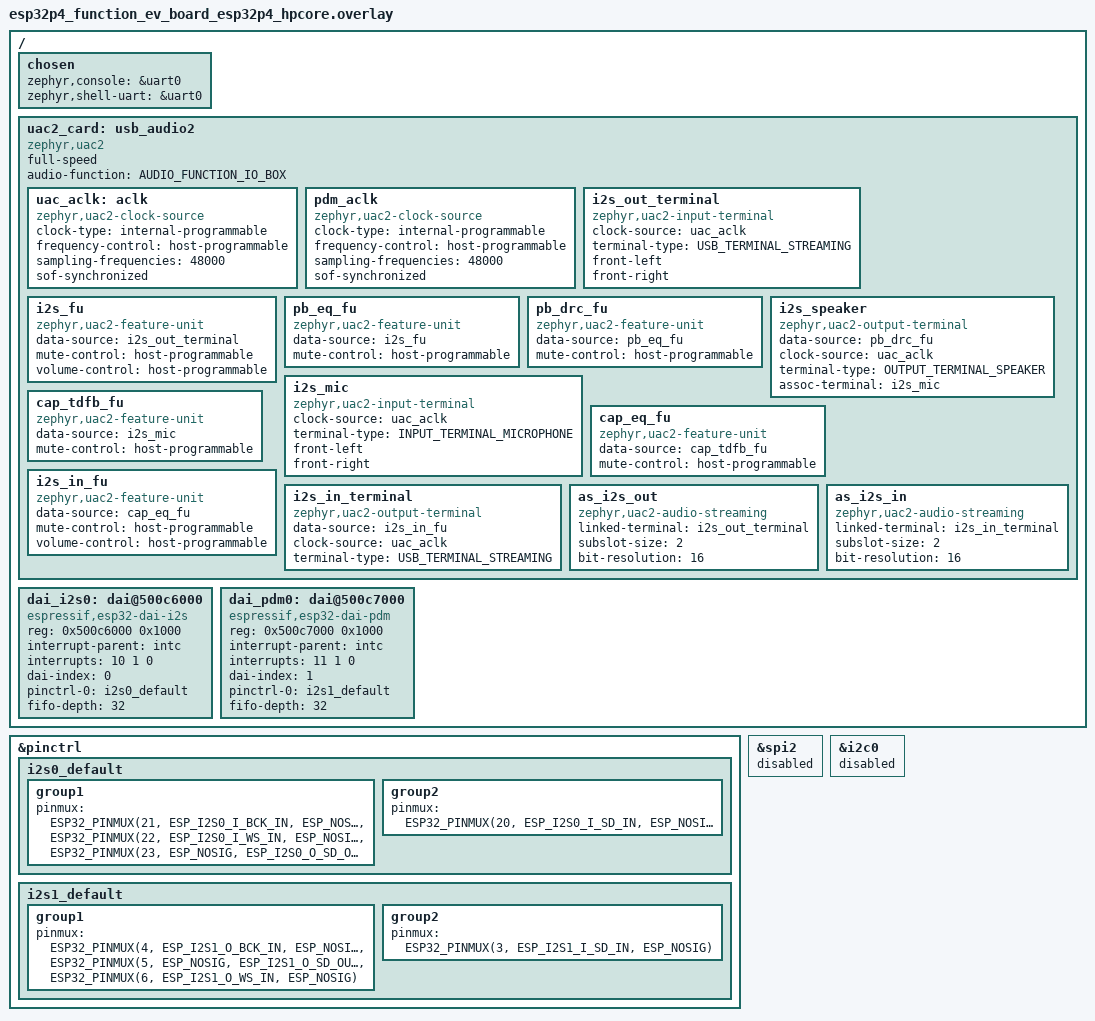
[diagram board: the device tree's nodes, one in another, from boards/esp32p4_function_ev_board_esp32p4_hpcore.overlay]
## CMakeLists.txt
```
# SPDX-License-Identifier: Apache-2.0

cmake_minimum_required(VERSION 3.21.0)

# Board specific overlays (these must be before find_package(Zephyr))
# -------------------------------------------------------------------

# Intel ACE3.x and newer (e.g. ptl, wcl, nvl): if "os_linux_overlay"
# used, also add "ll_userspace_overlay". The board target may be given
# in full in BOARD ("intel_adsp/ace30/ptl") or split into BOARD and
# BOARD_QUALIFIERS ("intel_adsp" + "ace30/ptl"), so match on both.
if(DEFINED EXTRA_CONF_FILE AND
   "${BOARD}/${BOARD_QUALIFIERS}" MATCHES "^intel_adsp/ace[3-9][0-9]/")
  string(FIND "${EXTRA_CONF_FILE}" "os_linux_overlay" _linux_overlay_idx)
  string(FIND "${EXTRA_CONF_FILE}" "ll_userspace_overlay" _ll_overlay_idx)
  if(_linux_overlay_idx GREATER_EQUAL 0 AND _ll_overlay_idx LESS 0)
    list(APPEND EXTRA_CONF_FILE
      "${CMAKE_CURRENT_SOURCE_DIR}/ll_userspace_overlay.conf")
  endif()
endif()

find_package(Zephyr HINTS $ENV{ZEPHYR_BASE})
project(sample_sof)

if(NOT ZEPHYR_SOF_MODULE)
  add_subdirectory(../zephyr sof_zephyr)
endif()

target_sources(app PRIVATE
    src/main.c
  )

target_sources_ifdef(CONFIG_USB_DEVICE_STACK_NEXT app PRIVATE
    src/usbd_init.c
  )

zephyr_library_include_directories(app PUBLIC
    ${CMAKE_CURRENT_SOURCE_DIR}/../src/include
  )

if(CONFIG_XTENSA)
  zephyr_library_include_directories(app PUBLIC
      ${CMAKE_CURRENT_SOURCE_DIR}/../src/arch/xtensa/include
    )
endif()

if(CONFIG_SOF_FULL_ZEPHYR_APPLICATION AND NOT CONFIG_XTENSA)
  target_include_directories(app PRIVATE
      ${CMAKE_CURRENT_SOURCE_DIR}/src
      ${CMAKE_CURRENT_SOURCE_DIR}/../zephyr/include
      ${CMAKE_CURRENT_SOURCE_DIR}/../src/platform/${PLATFORM}/include
      ${PROJECT_BINARY_DIR}/include/generated
    )

  target_link_libraries(app PRIVATE SOF -Wl,--start-group modules_sof sof_kernel -Wl,--end-group)
  if(TARGET uuid_reg_h)
    add_dependencies(app uuid_reg_h modules_sof sof_kernel)
  endif()
endif()

if(COMMAND sof_append_relative_path_definitions)
  sof_append_relative_path_definitions(app)
endif()
```

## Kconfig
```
config SCHED_CPU_MASK_PIN_ONLY
	default y if SMP

# Allow compiler to determine whether to generate FLIX instructions.
choice COMPILER_CODEGEN_VLIW
	default COMPILER_CODEGEN_VLIW_AUTO if "$(ZEPHYR_TOOLCHAIN_VARIANT)" = "xt-clang"
endchoice

source "Kconfig.zephyr"
osource "samples/subsys/usb/common/Kconfig.sample_usbd"

if !ZEPHYR_SOF_MODULE
rsource "../zephyr/Kconfig"
endif

if SOC_FAMILY_INTEL_ADSP
	rsource "boards/intel_adsp/Kconfig.defconfig"
endif
```

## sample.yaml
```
---
sample:
  description: Audio with SOF
  name: sof
common:
  tags: audio
  modules:
    - sof
tests:
  sample.audio.sof:
    tags: sof
    build_only: true
    platform_allow:
      - intel_adsp/cavs25
      - intel_adsp/ace15_mtpm
      - intel_adsp/ace20_lnl
      - intel_adsp/ace30/ptl
      - intel_adsp/ace30/ptl/sim
      - intel_adsp/ace30/wcl
      - intel_adsp/ace30/wcl/sim
      - intel_adsp/ace40/nvl
      - imx8qm_mek/mimx8qm6/adsp
      - imx8qxp_mek/mimx8qx6/adsp
      - imx8mp_evk/mimx8ml8/adsp
      - imx8ulp_evk/mimx8ud7/adsp

    integration_platforms:
      - intel_adsp/cavs25  # TGL
      - intel_adsp/ace15_mtpm  # MTL
      - intel_adsp/ace20_lnl
      - imx8qm_mek/mimx8qm6/adsp
      - imx8qxp_mek/mimx8qx6/adsp
      - imx8mp_evk/mimx8ml8/adsp
      - imx8ulp_evk/mimx8ud7/adsp
```

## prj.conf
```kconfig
CONFIG_BUILD_OUTPUT_BIN=n

# The additional stripped .elf files are deterministic.
# This adds very few files in the build directory and has
# absolutely no other effect whatsoever.
# See on-going discussion in
# https://github.com/zephyrproject-rtos/zephyr/pull/51954
# and usage in xtensa-build-zephyr.py
CONFIG_BUILD_OUTPUT_STRIPPED=y

CONFIG_HAVE_AGENT=n

# Since Zephyr commit f0daf904bb0202c PICOLIBC is the new default.
# We need more time to test and evaluate.
CONFIG_MINIMAL_LIBC=y

CONFIG_ZEPHYR_LOG=y
CONFIG_LOG=y
CONFIG_LOG_PRINTK=y
# Log processing is offloaded to a low-priority thread.
CONFIG_LOG_MODE_DEFERRED=y
# Wake the low-priority log thread every time new log
# messages are available
CONFIG_LOG_PROCESS_TRIGGER_THRESHOLD=1
# Frontend buffer must be large enough to cover all
# typical bursts of log messages.
CONFIG_LOG_BUFFER_SIZE=4096
# Use stack that is sufficient for SOF backends
CONFIG_LOG_PROCESS_THREAD_STACK_SIZE=4096
# Use Linux kernel style timestamp format
CONFIG_LOG_OUTPUT_FORMAT_LINUX_TIMESTAMP=y

# Requires heap_info() be implemented, but no Zephyr wrapper
CONFIG_DEBUG_MEMORY_USAGE_SCAN=n

# Ensure -O2 (or similar) is used for optimization
CONFIG_SPEED_OPTIMIZATIONS=y

# Zephyr top-level default of -fno-strict-overflow is
# not a good fit for audio DSP code
CONFIG_COMPILER_OPT="-fstrict-overflow"

CONFIG_SCHED_DEADLINE=y
CONFIG_SCHED_CPU_MASK=y

# Fix the sys ticks value  until following bugs are solved:
# - https://github.com/zephyrproject-rtos/zephyr/issues/46378
CONFIG_SYS_CLOCK_TICKS_PER_SEC=15000
CONFIG_DAI=y
CONFIG_HEAP_MEM_POOL_SIZE=2048
```

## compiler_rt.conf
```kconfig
CONFIG_COMPILER_RT_RTLIB=y
```

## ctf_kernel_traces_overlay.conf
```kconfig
# enable traces from Zephyr kernel

CONFIG_TRACING_BACKEND_ADSP_MEMORY_WINDOW=y
CONFIG_TRACING_ASYNC=n
CONFIG_TRACING_SYNC=y
CONFIG_TRACING=y
CONFIG_TRACING_CTF=y
CONFIG_THREAD_NAME=y
CONFIG_DEBUG_THREAD_INFO=y
```

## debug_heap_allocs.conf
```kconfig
# Use this overlay to increase log verbosity for
# all runtime heap allocs.
#
# Logs (LOG_INF) are emitted from all heap types (system heap 'sof_heap',
# virtual heap allocator, vregions, ...)
#

CONFIG_SYS_HEAP_RUNTIME_STATS=y
CONFIG_SYS_MEM_BLOCKS_RUNTIME_STATS=y
```

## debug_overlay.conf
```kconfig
CONFIG_DEBUG=y
CONFIG_ASSERT=y

CONFIG_ZTEST_NO_YIELD=n
CONFIG_ZTEST_SUMMARY=n
CONFIG_ZTEST_TEST_DELAY_MS=1
CONFIG_SOF_BOOT_TEST_ALLOWED=y
CONFIG_TEST_EXTRA_STACK_SIZE=7168

CONFIG_DAI_VERBOSE_GLITCH_WARNINGS=y

# Following options can be enabled additionally,
# but will incur a higher runtime cost, so are thus
# disabled by default.
#
# CONFIG_STACK_SENTINEL=y
# CONFIG_SYS_HEAP_VALIDATE=y
# CONFIG_SPIN_VALIDATE=y
# CONFIG_SPIN_LOCK_TIME_LIMIT=50000

CONFIG_COLD_STORE_EXECUTE_DEBUG=y

# GDB stub

CONFIG_GDBSTUB=y
CONFIG_GDBSTUB_ENTER_IMMEDIATELY=n

# Logging options
# Set default runtime log level to INFO (3) to maintain expected behavior in SOF CI.
# This ensures firmware starts with INFO level logging, same as previous configuration.
# Testing with runtime filtering enabled ensures the same feature set is validated.
# Note: This setting has no effect if CONFIG_LOG_RUNTIME_FILTERING is disabled.
CONFIG_LOG_RUNTIME_DEFAULT_LEVEL=3
```

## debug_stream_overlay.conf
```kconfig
# Enable debug-stream protocol
CONFIG_SOF_DEBUG_STREAM_SLOT=y
# Enable text message sending with ds_msg()
CONFIG_SOF_DEBUG_STREAM_TEXT_MSG=y
# Add thread_info-client for debug stream
CONFIG_SOF_DEBUG_STREAM_THREAD_INFO=y
# Zephyr option for storing human readable thread names
CONFIG_THREAD_NAME=y
# For Zephyr to compile with thread names on PTL we need to increase THREAD_BYTES
CONFIG_MAX_THREAD_BYTES=4
# Shrink number of CPU sections
# As the number of supported cores shrink, the available circular
# buffer size increases. This means increased bandwidth. This is
# particularly useful, when debugging a problem on core 0.
#CONFIG_SOF_DEBUG_STREAM_SLOT_FORCE_MAX_CPUS=1

# Direct the assert prints to debug stream
# This option obeys CONFIG_EXCEPTION_DUMP_HOOK_ONLY. If it is selected
# the assert print is sent only to debug stream. Without it the assert
# prints are printed with vprintk too,
CONFIG_SOF_DEBUG_STREAM_TEXT_MSG_ASSERT_PRINT=y

# Debug window slot configuration 1
# The CONFIG_SOF_TELEMETRY uses slot 2, but with performance and IO-performance
# it extends beyond slot 3.
CONFIG_MEMORY_WIN_2_SIZE=16384
CONFIG_SOF_TELEMETRY_PERFORMANCE_MEASUREMENTS=n
CONFIG_SOF_TELEMETRY_IO_PERFORMANCE_MEASUREMENTS=n

# If we turn telemetry off altogether, we can use slot 2. Slot 1 is used by mtrace
#CONFIG_SOF_DEBUG_STREAM_SLOT_NUMBER=2
#CONFIG_SOF_TELEMETRY=n
#CONFIG_SOF_TELEMETRY_PERFORMANCE_MEASUREMENTS=n
#CONFIG_SOF_TELEMETRY_IO_PERFORMANCE_MEASUREMENTS=n

# Enable Zephyr exception printing hook; debug stream is sensitive to this option too
CONFIG_EXCEPTION_DUMP_HOOK=y
# Do not try to send exception prints through logs; this causes problems on PTL with mtrace
CONFIG_EXCEPTION_DUMP_HOOK_ONLY=y
```

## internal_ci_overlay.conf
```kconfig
#
# Overlay definitions to build SOF firmware for internal CI
#
# The default SOF build (board config files) targets the Linux SOF
# driver. This overlay restores the configuration that was used
# for non-Linux builds before Linux became the default.
#
# When this overlay is used, app/CMakeLists.txt also:
#  - does not include the Intel ACE3.x+ LL userspace overlay
#    (ll_userspace_overlay.conf)
#  - includes the board specific internal CI overlay from
#    overlays/internal_ci/<board>.conf, if present
#

# Do not restrict firmware to features supported by stable
# Linux SOF driver versions. This also enables the additional
# virtual heap buffers (VIRTUAL_HEAP_EXTENDED) on platforms
# that support them.
CONFIG_SOF_OS_LINUX_COMPAT_PRIORITY=n
```

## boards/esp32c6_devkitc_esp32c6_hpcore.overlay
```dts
#include <zephyr/dt-bindings/interrupt-controller/esp-esp32c6-intmux.h>

/ {
	chosen {
		zephyr,console = &usb_serial;
		zephyr,shell-uart = &usb_serial;
	};

	dai_i2s0: dai@6000c000 {
		compatible = "espressif,esp32-dai-i2s";
		status = "okay";
		reg = <0x6000c000 0x1000>;
		interrupt-parent = <&intc>;
		interrupts = <I2S1_INTR_SOURCE IRQ_DEFAULT_PRIORITY 0>;
		dai-index = <0>;
		fifo-depth = <32>;
	};
};

&dma {
	status = "okay";
};

&usb_serial {
	status = "okay";
};

&i2c0 {
	status = "disabled";
};

&uart0 {
	status = "disabled";
};
```

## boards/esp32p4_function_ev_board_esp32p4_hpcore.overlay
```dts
#include <zephyr/dt-bindings/usb/audio.h>
#include <zephyr/dt-bindings/pinctrl/esp32p4-pinctrl.h>

/ {
	chosen {
		zephyr,console = &uart0;
		zephyr,shell-uart = &uart0;
	};

	uac2_card: usb_audio2 {
		compatible = "zephyr,uac2";
		status = "okay";
		full-speed;
		audio-function = <AUDIO_FUNCTION_IO_BOX>;

		uac_aclk: aclk {
			compatible = "zephyr,uac2-clock-source";
			clock-type = "internal-programmable";
			frequency-control = "host-programmable";
			sampling-frequencies = <48000>;
			sof-synchronized;
		};

		pdm_aclk: pdm_aclk {
			compatible = "zephyr,uac2-clock-source";
			clock-type = "internal-programmable";
			frequency-control = "host-programmable";
			sampling-frequencies = <48000>;
			sof-synchronized;
		};

		/* ===== Playback from Host (ISO OUT) ===== */
		i2s_out_terminal: i2s_out_terminal {
			compatible = "zephyr,uac2-input-terminal";
			clock-source = <&uac_aclk>;
			terminal-type = <USB_TERMINAL_STREAMING>;
			front-left;
			front-right;
		};

		i2s_fu: i2s_fu {
			compatible = "zephyr,uac2-feature-unit";
			data-source = <&i2s_out_terminal>;
			mute-control = "host-programmable";
			volume-control = "host-programmable";
		};

		pb_eq_fu: pb_eq_fu {
			compatible = "zephyr,uac2-feature-unit";
			data-source = <&i2s_fu>;
			mute-control = "host-programmable";
		};

		pb_drc_fu: pb_drc_fu {
			compatible = "zephyr,uac2-feature-unit";
			data-source = <&pb_eq_fu>;
			mute-control = "host-programmable";
		};

		i2s_speaker: i2s_speaker {
			compatible = "zephyr,uac2-output-terminal";
			data-source = <&pb_drc_fu>;
			clock-source = <&uac_aclk>;
			terminal-type = <OUTPUT_TERMINAL_SPEAKER>;
			assoc-terminal = <&i2s_mic>;
		};

		/* ===== Capture to Host (ISO IN) ===== */
		i2s_mic: i2s_mic {
			compatible = "zephyr,uac2-input-terminal";
			clock-source = <&uac_aclk>;
			terminal-type = <INPUT_TERMINAL_MICROPHONE>;
			front-left;
			front-right;
		};

		cap_tdfb_fu: cap_tdfb_fu {
			compatible = "zephyr,uac2-feature-unit";
			data-source = <&i2s_mic>;
			mute-control = "host-programmable";
		};

		cap_eq_fu: cap_eq_fu {
			compatible = "zephyr,uac2-feature-unit";
			data-source = <&cap_tdfb_fu>;
			mute-control = "host-programmable";
		};

		i2s_in_fu: i2s_in_fu {
			compatible = "zephyr,uac2-feature-unit";
			data-source = <&cap_eq_fu>;
			mute-control = "host-programmable";
			volume-control = "host-programmable";
		};

		i2s_in_terminal: i2s_in_terminal {
			compatible = "zephyr,uac2-output-terminal";
			data-source = <&i2s_in_fu>;
			clock-source = <&uac_aclk>;
			terminal-type = <USB_TERMINAL_STREAMING>;
		};

		/* Audio Streaming Interfaces */
		as_i2s_out: as_i2s_out {
			compatible = "zephyr,uac2-audio-streaming";
			linked-terminal = <&i2s_out_terminal>;
			subslot-size = <2>;
			bit-resolution = <16>;
		};

		as_i2s_in: as_i2s_in {
			compatible = "zephyr,uac2-audio-streaming";
			linked-terminal = <&i2s_in_terminal>;
			subslot-size = <2>;
			bit-resolution = <16>;
		};
	};

	/* ESP32 DAI Nodes */
	dai_i2s0: dai@500c6000 {
		compatible = "espressif,esp32-dai-i2s";
		status = "okay";
		reg = <0x500c6000 0x1000>;
		interrupt-parent = <&intc>;
		interrupts = <10 1 0>;
		dai-index = <0>;
		pinctrl-0 = <&i2s0_default>;
		pinctrl-names = "default";
		fifo-depth = <32>;
	};

	dai_pdm0: dai@500c7000 {
		compatible = "espressif,esp32-dai-pdm";
		status = "okay";
		reg = <0x500c7000 0x1000>;
		interrupt-parent = <&intc>;
		interrupts = <11 1 0>;
		dai-index = <1>;
		pinctrl-0 = <&i2s1_default>;
		pinctrl-names = "default";
		fifo-depth = <32>;
	};
};

&pinctrl {
	i2s0_default: i2s0_default {
		group1 {
			pinmux = <ESP32_PINMUX(21, ESP_I2S0_I_BCK_IN, ESP_NOSIG)>,
				 <ESP32_PINMUX(22, ESP_I2S0_I_WS_IN, ESP_NOSIG)>,
				 <ESP32_PINMUX(23, ESP_NOSIG, ESP_I2S0_O_SD_OUT)>;
		};
		group2 {
			pinmux = <ESP32_PINMUX(20, ESP_I2S0_I_SD_IN, ESP_NOSIG)>;
		};
	};

	i2s1_default: i2s1_default {
		group1 {
			pinmux = <ESP32_PINMUX(4, ESP_I2S1_O_BCK_IN, ESP_NOSIG)>,
				 <ESP32_PINMUX(5, ESP_NOSIG, ESP_I2S1_O_SD_OUT)>,
				 <ESP32_PINMUX(6, ESP_I2S1_O_WS_IN, ESP_NOSIG)>;
		};
		group2 {
			pinmux = <ESP32_PINMUX(3, ESP_I2S1_I_SD_IN, ESP_NOSIG)>;
		};
	};
};

&spi2 {
	status = "disabled";
};

&i2c0 {
	status = "disabled";
};
```

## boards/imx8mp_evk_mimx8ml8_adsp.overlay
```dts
/*
 * Copyright 2024 NXP
 *
 * SPDX-License-Identifier: Apache-2.0
 */

/ {
	host_dma: dma {
		compatible = "nxp,sof-host-dma";
		dma-channels = <32>;
		#dma-cells = <0>;
	};
};

&sdma3 {
	status = "okay";
};

&sai3 {
	rx-fifo-watermark = <65>;
	tx-fifo-watermark = <65>;
	fifo-depth = <128>;
	rx-sync-mode = <1>;
	status = "okay";
};

&micfil {
	status = "okay";
};
```

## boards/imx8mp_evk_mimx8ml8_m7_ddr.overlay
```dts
/*
 * Copyright 2026 NXP
 *
 * SPDX-License-Identifier: Apache-2.0
 */

/ {
	host_dma: dma {
		compatible = "nxp,sof-host-dma";
		dma-channels = <32>;
		#dma-cells = <0>;
	};
};

&sdma3 {
	status = "okay";
};

&sai3 {
	pinctrl-0 = <&sai3_default>;
	pinctrl-names = "default";
	rx-fifo-watermark = <64>;
	tx-fifo-watermark = <64>;
	fifo-depth = <96>;
	rx-sync-mode = <1>;
	status = "okay";
};
```

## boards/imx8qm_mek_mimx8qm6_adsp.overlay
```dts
/*
 * Copyright 2023 NXP
 *
 * SPDX-License-Identifier: Apache-2.0
 */

/ {
	host_dma: dma {
		compatible = "nxp,sof-host-dma";
		dma-channels = <32>;
		#dma-cells = <0>;
	};
};

&lpuart2 {
	/* note for developers: this is disabled
	 * because the firmware running on one of the M4
	 * cores uses the same LPUART instance. As such,
	 * to debug you need to make sure that:
	 *	1) Your SOF DTS doesn't include the RPMSG
	 *	DTS but instead the base DTS (which is
	 *	"imx8qm-mek.dts")
	 *	2) Your u-boot doesn't include the M4 firmware
	 *	images.
	 */
	status = "disabled";
};

&sai1 {
	rx-fifo-watermark = <48>;
	tx-fifo-watermark = <2>;
	fifo-depth = <48>;
	rx-sync-mode = <1>;
	status = "okay";
};

&esai0 {
	fifo-depth = <96>;
	/* note: not the same semantic as SAI TX watermark. For ESAI
	 * the DMA requests are generated when number of empty slots
	 * in the transmit FIFO reaches the chosen watermark value.
	 * In this case, DMA requests will be generated when transmit
	 * FIFO has 128 empty slots (equivalent to the FIFO having
	 * 2 words since the FIFO depth is 128 words).
	 */
	tx-fifo-watermark = <126>;
	rx-fifo-watermark = <96>;
	/* needed for internal CS42888 workaround. Remove when possible */
	esai-clock-configuration = <ESAI_CLOCK_SCKR ESAI_CLOCK_INPUT>,
				<ESAI_CLOCK_FSR ESAI_CLOCK_INPUT>;
	status = "okay";
};

&edma0 {
	status = "okay";
};
```

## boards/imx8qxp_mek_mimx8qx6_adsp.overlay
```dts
/*
 * Copyright 2023 NXP
 *
 * SPDX-License-Identifier: Apache-2.0
 */

/ {
	host_dma: dma {
		compatible = "nxp,sof-host-dma";
		dma-channels = <32>;
		#dma-cells = <0>;
	};
};

&sai1 {
	rx-fifo-watermark = <48>;
	tx-fifo-watermark = <2>;
	fifo-depth = <48>;
	rx-sync-mode = <1>;
	status = "okay";
};

&esai0 {
	fifo-depth = <96>;
	/* note: not the same semantic as SAI TX watermark. For ESAI
	* the DMA requests are generated when number of empty slots
	* in transmit FIFO reaches the chosen watermark value.
	* In this case, DMA requests will be generated when transmit
	* FIFO has 126 empty slots (equivalent to the FIFO having
	* 2 words since the FIFO depth is 128 words).
	*/
	tx-fifo-watermark = <126>;
	rx-fifo-watermark = <96>;
	/* needed for internal CS42888 workaround. Remove when possible */
	esai-clock-configuration = <ESAI_CLOCK_SCKR ESAI_CLOCK_INPUT>,
				<ESAI_CLOCK_FSR ESAI_CLOCK_INPUT>;
	status = "okay";
};

&edma0 {
	status = "okay";
};
```

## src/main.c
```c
/*
 * Copyright (c) 2020 Intel Corporation.
 *
 * SPDX-License-Identifier: Apache-2.0
 */

#include <zephyr/kernel.h>
#include <sof/boot_test.h>
#include <zephyr/logging/log.h>

#if defined(CONFIG_PLATFORM_TEENSY41)
#include <zephyr/device.h>
#include <zephyr/usb/usbd.h>
#include <zephyr/usb/class/usbd_uac2.h>
#include <sample_usbd.h>
#include <sof/platform.h>
#include <sof/audio/pipeline/static_pipeline.h>
#endif

LOG_MODULE_REGISTER(main, LOG_LEVEL_DBG);

/* define qemu boot tests if any qemu target is defined, add targets to end */
#if defined(CONFIG_BOARD_QEMU_XTENSA_DC233C) ||\
    defined(CONFIG_BOARD_QEMU_XTENSA_DC233C_MMU)
#define QEMU_BOOT_TESTS
#endif

/**
 * Should be included from sof/schedule/task.h
 * but triggers include chain issue
 * FIXME
 */
int sof_main(int argc, char *argv[]);

/**
 * TODO: Here comes SOF initialization
 */

static int sof_app_main(void)
{
	int ret;

	LOG_INF("SOF on %s", CONFIG_BOARD);

	/* sof_main is actually SOF initialization */
	ret = sof_main(0, NULL);
	if (ret) {
		LOG_ERR("SOF initialization failed");
	}

	LOG_INF("SOF initialized");

#if defined(CONFIG_PLATFORM_TEENSY41)
	ret = sof_static_topology_init(&g_teensy41_static_topology);
	if (ret < 0) {
		LOG_ERR("Static topology initialization failed: %d", ret);
		return ret;
	}

	const struct device *uac2_dev = DEVICE_DT_GET_ONE(zephyr_uac2);

	if (device_is_ready(uac2_dev)) {
		usbd_uac2_set_ops(uac2_dev, sof_static_uac2_get_ops(), NULL);
	} else {
		LOG_ERR("UAC2 device not ready");
	}

	struct usbd_context *sample_usbd = sample_usbd_init_device(NULL);

	if (sample_usbd) {
		usbd_enable(sample_usbd);
		LOG_INF("SOF USB UAC2 device and static pipelines started");
	} else {
		LOG_ERR("Failed to initialize USB device context");
	}
#endif

#ifdef CONFIG_ARCH_POSIX_LIBFUZZER
	/* Workaround for an apparent timing bug in libfuzzer+asan.
	 * If the initial/main thread is allowed to return, ASAN will
	 * fairly reliably report a "stack overflow" where the ESP and
	 * EPC (instruction pointer!) registers are both set to the
	 * same value, which is non-sensical.  See some discussion in
	 * https://github.com/zephyrproject-rtos/zephyr/pull/52769
	 *
	 * But suspending the main thread instead of aborting is cheap
	 * and easy.
	 */
	k_thread_suspend(k_current_get());
#endif
	return 0;
}

#if defined(QEMU_BOOT_TESTS)
/* cleanly exit qemu so CI can continue and check test results */
static inline void qemu_xtensa_exit(int status)
{
	register int syscall_id __asm__ ("a2") = 1;      /* SYS_exit is 1 */
	register int exit_status __asm__ ("a3") = status;

	__asm__ __volatile__ (
		"simcall\n"
		:
		: "r" (syscall_id), "r" (exit_status)
		: "memory"
	);
}
#endif

#ifdef CONFIG_REBOOT
void sys_arch_reboot(int type)
{
#if defined(QEMU_BOOT_TESTS)
	qemu_xtensa_exit(type);
#endif
	while (1) {
		k_cpu_idle();
	}
}
#endif

#if CONFIG_ZTEST
void test_main(void)
{
	sof_app_main();
#if CONFIG_SOF_BOOT_TEST && (defined(QEMU_BOOT_TESTS) || CONFIG_SOF_BOOT_TEST_STANDALONE)
	sof_run_boot_tests();
#if defined(QEMU_BOOT_TESTS)
	/* qemu_xtensa_exit() only exists for QEMU targets; a standalone
	 * boot test (e.g. native_sim) just returns from test_main()
	 */
	qemu_xtensa_exit(0);
#endif
#endif
}
#else
int main(void)
{
	return sof_app_main();
}
#endif
```

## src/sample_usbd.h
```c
/*
 * Copyright (c) 2023 Nordic Semiconductor ASA.
 *
 * SPDX-License-Identifier: Apache-2.0
 */

#ifndef ZEPHYR_SAMPLES_SUBSYS_USB_COMMON_SAMPLE_USBD_H
#define ZEPHYR_SAMPLES_SUBSYS_USB_COMMON_SAMPLE_USBD_H

#include <stdint.h>
#include <zephyr/usb/usbd.h>

struct usbd_context *sample_usbd_init_device(usbd_msg_cb_t msg_cb);
struct usbd_context *sample_usbd_setup_device(usbd_msg_cb_t msg_cb);

#endif /* ZEPHYR_SAMPLES_SUBSYS_USB_COMMON_SAMPLE_USBD_H */
```

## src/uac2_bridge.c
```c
// SPDX-License-Identifier: BSD-3-Clause
/*
 * Copyright (c) 2026 Sound Open Firmware (SOF) Project
 */

#include "uac2_bridge.h"
#include <sof/audio/pipeline/static_pipeline.h>
#include <sof/audio/usb_audio.h>
#if CONFIG_COMP_BT_AUDIO
#include <sof/audio/bt_audio.h>
#include <sof/audio/bt_service.h>
#endif
#include <zephyr/logging/log.h>
#include <zephyr/usb/usbd.h>
#include <zephyr/usb/class/usbd_uac2.h>
#include <zephyr/device.h>

LOG_MODULE_REGISTER(uac2_bridge, CONFIG_SOF_LOG_LEVEL);

#if defined(CONFIG_USBD_AUDIO2_CLASS)
#define PLAYBACK_FU_ID       UAC2_ENTITY_ID(DT_NODELABEL(i2s_fu))
#define PLAYBACK_EQ_FU_ID    UAC2_ENTITY_ID(DT_NODELABEL(pb_eq_fu))
#define PLAYBACK_DRC_FU_ID   UAC2_ENTITY_ID(DT_NODELABEL(pb_drc_fu))
#define CAPTURE_EQ_FU_ID     UAC2_ENTITY_ID(DT_NODELABEL(cap_eq_fu))
#define CAPTURE_FU_ID        UAC2_ENTITY_ID(DT_NODELABEL(i2s_in_fu))
#define PLAYBACK_TERM_ID     UAC2_ENTITY_ID(DT_NODELABEL(i2s_out_terminal))
#define CAPTURE_TERM_ID      UAC2_ENTITY_ID(DT_NODELABEL(i2s_in_terminal))
#else
#define PLAYBACK_FU_ID       1
#define PLAYBACK_EQ_FU_ID    2
#define PLAYBACK_DRC_FU_ID   3
#define CAPTURE_EQ_FU_ID     4
#define CAPTURE_FU_ID        5
#define PLAYBACK_TERM_ID     6
#define CAPTURE_TERM_ID      7
#endif

#if defined(CONFIG_NOCACHE_MEMORY)
K_MEM_SLAB_DEFINE_IN_SECT_STATIC(uac2_rx_slab, __nocache, 256, 32, 64);
K_MEM_SLAB_DEFINE_IN_SECT_STATIC(uac2_tx_slab, __nocache, 256, 64, 64);
#else
K_MEM_SLAB_DEFINE_STATIC(uac2_rx_slab, 256, 32, 64);
K_MEM_SLAB_DEFINE_STATIC(uac2_tx_slab, 256, 64, 64);
#endif

static struct {
	bool playback_active;
	bool capture_active;
	bool microframes;
	uint32_t sample_rate;
	int16_t playback_volume;
	bool playback_mute;
	int16_t capture_volume;
	bool capture_mute;
} g_uac2_state = {
	.sample_rate = 48000,
};

static uint32_t s_sof_diag_cnt;

static void sof_uac2_send_capture_pending(const struct device *dev)
{
	if (!g_uac2_state.capture_active || !dev) {
		return;
	}

	uint32_t rate = g_uac2_state.sample_rate ? g_uac2_state.sample_rate : 48000;
	uint32_t frame_bytes;

	if (g_uac2_state.microframes) {
		frame_bytes = (rate / 8000) * 4;
	} else {
		frame_bytes = (rate / 1000) * 4;
	}
	if (frame_bytes == 0 || frame_bytes > 512) {
		frame_bytes = g_uac2_state.microframes ? 24 : 192;
	}

#if CONFIG_COMP_BT_AUDIO
	if (bt_service_get_route() != SOF_AUDIO_ROUTE_USB_BT &&
	    !usb_audio_has_capture_data(frame_bytes)) {
		return;
	}
#else
	if (!usb_audio_has_capture_data(frame_bytes)) {
		return;
	}
#endif

	for (int iter = 0; iter < 2; iter++) {
		void *buf = NULL;
		if (k_mem_slab_alloc(&uac2_tx_slab, &buf, K_NO_WAIT) != 0) {
			static uint32_t s_slab_alloc_fails;
			s_slab_alloc_fails++;
			if (s_slab_alloc_fails <= 5 || s_slab_alloc_fails % 100 == 0) {
				LOG_WRN("Failed to allocate UAC2 TX slab block (%u)",
					s_slab_alloc_fails);
			}
			break;
		}

		bool have_data = false;
#if CONFIG_COMP_BT_AUDIO
		if (bt_service_get_route() == SOF_AUDIO_ROUTE_USB_BT) {
			have_data = bt_audio_peek_capture_data(buf, frame_bytes);
		} else
#endif
		{
			have_data = usb_audio_peek_capture_data(buf, frame_bytes);
		}

		if (!have_data) {
			k_mem_slab_free(&uac2_tx_slab, buf);
			break;
		}

		if (g_uac2_state.capture_mute) {
			memset(buf, 0, frame_bytes);
		}

		int ret = usbd_uac2_send(dev, CAPTURE_TERM_ID, buf, frame_bytes);
		if (ret == 0) {
			if (!g_uac2_state.capture_mute) {
#if CONFIG_COMP_BT_AUDIO
				if (bt_service_get_route() == SOF_AUDIO_ROUTE_USB_BT) {
					bt_audio_consume_capture_data(frame_bytes);
				} else
#endif
				{
					usb_audio_consume_capture_data(frame_bytes);
				}
			}
		} else {
			k_mem_slab_free(&uac2_tx_slab, buf);
			break;
		}
	}
}

static void sof_uac2_sof_cb(const struct device *dev, void *user_data)
{
	ARG_UNUSED(user_data);

	if (g_uac2_state.playback_active || g_uac2_state.capture_active) {
		s_sof_diag_cnt++;
		if (s_sof_diag_cnt % 1000 == 0) {
			LOG_DBG("[DIAG SOF %u] Active streaming", s_sof_diag_cnt);
		}
	} else {
		s_sof_diag_cnt = 0;
	}

	if (g_uac2_state.capture_active && dev) {
		sof_uac2_send_capture_pending(dev);
	}
}

static void sof_uac2_terminal_update_cb(const struct device *dev, uint8_t terminal,
					bool enabled, bool microframes, void *user_data)
{
	ARG_UNUSED(dev);
	ARG_UNUSED(user_data);

	LOG_INF("[UAC2 Terminal] update: terminal %u, enabled %d, microframes %d",
		terminal, enabled, microframes);

	g_uac2_state.microframes = microframes;

	if (terminal == PLAYBACK_TERM_ID) {
		g_uac2_state.playback_active = enabled;
		sof_static_pipeline_trigger_by_uac2_term(terminal, enabled);
	} else if (terminal == CAPTURE_TERM_ID) {
		g_uac2_state.capture_active = enabled;
		sof_static_pipeline_trigger_by_uac2_term(terminal, enabled);
	}
}

static void *sof_uac2_get_recv_buf(const struct device *dev, uint8_t terminal,
				   uint16_t size, void *user_data)
{
	ARG_UNUSED(dev);
	ARG_UNUSED(terminal);
	ARG_UNUSED(size);
	ARG_UNUSED(user_data);

	void *buf = NULL;
	if (k_mem_slab_alloc(&uac2_rx_slab, &buf, K_NO_WAIT) != 0) {
		return NULL;
	}
	return buf;
}

static void sof_uac2_data_recv_cb(const struct device *dev, uint8_t terminal,
				  void *buf, uint16_t size, void *user_data)
{
	ARG_UNUSED(dev);
	ARG_UNUSED(terminal);
	ARG_UNUSED(user_data);

	if (buf && size > 0) {
		if (g_uac2_state.playback_mute) {
			memset(buf, 0, size);
		}
#if CONFIG_COMP_BT_AUDIO
		if (bt_service_get_route() == SOF_AUDIO_ROUTE_BT_DAI) {
			bt_audio_write_playback(buf, size);
		} else
#endif
		{
			usb_audio_feed_playback_data(buf, size);
		}
	}
}

static void sof_uac2_buf_release(const struct device *dev, uint8_t terminal,
				 void *buf, void *user_data)
{
	ARG_UNUSED(user_data);

	if (buf) {
		k_mem_slab_free(&uac2_tx_slab, buf);
	}

	if (terminal == CAPTURE_TERM_ID && dev) {
		sof_uac2_send_capture_pending(dev);
	}
}

static uint32_t sof_uac2_get_sample_rate(const struct device *dev, uint8_t clock_id,
					 void *user_data)
{
	ARG_UNUSED(dev);
	ARG_UNUSED(clock_id);
	ARG_UNUSED(user_data);

	return g_uac2_state.sample_rate ? g_uac2_state.sample_rate : 48000;
}

static int sof_uac2_set_sample_rate(const struct device *dev, uint8_t clock_id,
				    uint32_t rate, void *user_data)
{
	ARG_UNUSED(dev);
	ARG_UNUSED(clock_id);
	ARG_UNUSED(user_data);

	LOG_INF("Host set sample rate: %u Hz", rate);
	g_uac2_state.sample_rate = rate;
	sof_static_set_sample_rate(rate);
	usb_audio_set_playback_rate(rate);
	usb_audio_set_capture_rate(rate);
	return 0;
}

enum usbd_speed sample_usbd_get_speed(void);

static uint32_t sof_uac2_feedback_cb(const struct device *dev, uint8_t terminal,
				     void *user_data)
{
	ARG_UNUSED(dev);
	ARG_UNUSED(terminal);
	ARG_UNUSED(user_data);

	uint32_t rate = g_uac2_state.sample_rate ? g_uac2_state.sample_rate : 48000;

	if (sample_usbd_get_speed() == USBD_SPEED_HS) {
		return (uint32_t)(((uint64_t)rate << 16) / 8000);
	} else {
		return (uint32_t)(((uint64_t)rate << 14) / 1000);
	}
}

static int sof_uac2_set_feature_mute(const struct device *dev, uint8_t entity_id,
				     uint8_t channel, bool mute, void *user_data)
{
	ARG_UNUSED(dev);
	ARG_UNUSED(user_data);

	LOG_DBG("Host set mute/switch: entity=%u, ch=%u, mute=%d", entity_id, channel, mute);
	if (entity_id == PLAYBACK_FU_ID) {
		g_uac2_state.playback_mute = mute;
	} else if (entity_id == CAPTURE_FU_ID) {
		g_uac2_state.capture_mute = mute;
	}

	return sof_static_kcontrol_set_by_uac2(entity_id, channel, mute ? 1 : 0, false);
}

static int sof_uac2_get_feature_mute(const struct device *dev, uint8_t entity_id,
				     uint8_t channel, bool *mute, void *user_data)
{
	ARG_UNUSED(dev);
	ARG_UNUSED(user_data);

	if (!mute) {
		return -EINVAL;
	}

	if (entity_id == PLAYBACK_FU_ID) {
		*mute = g_uac2_state.playback_mute;
		return 0;
	} else if (entity_id == CAPTURE_FU_ID) {
		*mute = g_uac2_state.capture_mute;
		return 0;
	}

	int32_t val = 0;
	int ret = sof_static_kcontrol_get_by_uac2(entity_id, channel, &val, false);
	*mute = (ret == 0) ? (val != 0) : false;
	return 0;
}

static int sof_uac2_set_feature_volume(const struct device *dev, uint8_t entity_id,
				       uint8_t channel, int16_t volume, void *user_data)
{
	ARG_UNUSED(dev);
	ARG_UNUSED(user_data);

	LOG_DBG("Host set volume: entity=%u, ch=%u, vol=%d", entity_id, channel, volume);
	if (entity_id == PLAYBACK_FU_ID) {
		g_uac2_state.playback_volume = volume;
	} else if (entity_id == CAPTURE_FU_ID) {
		g_uac2_state.capture_volume = volume;
	}

	return sof_static_kcontrol_set_by_uac2(entity_id, channel, volume, true);
}

static int sof_uac2_get_feature_volume(const struct device *dev, uint8_t entity_id,
				       uint8_t channel, int16_t *volume, void *user_data)
{
	ARG_UNUSED(dev);
	ARG_UNUSED(user_data);

	if (!volume) {
		return -EINVAL;
	}

	if (entity_id == PLAYBACK_FU_ID) {
		*volume = g_uac2_state.playback_volume;
		return 0;
	} else if (entity_id == CAPTURE_FU_ID) {
		*volume = g_uac2_state.capture_volume;
		return 0;
	}

	int32_t val = 0;
	int ret = sof_static_kcontrol_get_by_uac2(entity_id, channel, &val, true);
	*volume = (ret == 0) ? (int16_t)val : 0;
	return 0;
}

static const struct uac2_ops g_uac2_ops = {
	.sof_cb = sof_uac2_sof_cb,
	.terminal_update_cb = sof_uac2_terminal_update_cb,
	.get_recv_buf = sof_uac2_get_recv_buf,
	.data_recv_cb = sof_uac2_data_recv_cb,
	.buf_release_cb = sof_uac2_buf_release,
	.feedback_cb = sof_uac2_feedback_cb,
	.get_sample_rate = sof_uac2_get_sample_rate,
	.set_sample_rate = sof_uac2_set_sample_rate,
	.set_feature_mute = sof_uac2_set_feature_mute,
	.get_feature_mute = sof_uac2_get_feature_mute,
	.set_feature_volume = sof_uac2_set_feature_volume,
	.get_feature_volume = sof_uac2_get_feature_volume,
};

const struct uac2_ops *sof_get_uac2_ops(void)
{
	return &g_uac2_ops;
}

#if defined(CONFIG_PLATFORM_NRF54L15)
extern const struct sof_static_topology g_nrf54l15_static_topology;
#elif defined(CONFIG_PLATFORM_NRF54LM20)
extern const struct sof_static_topology g_nrf54lm20_static_topology;
#endif

int sof_static_pipelines_init(struct sof *sof)
{
	ARG_UNUSED(sof);
#if defined(CONFIG_PLATFORM_NRF54L15)
	int ret = sof_static_topology_init(&g_nrf54l15_static_topology);
	if (ret < 0)
		return ret;

	sof_static_pipeline_trigger(1, true);
	return 0;
#elif defined(CONFIG_PLATFORM_NRF54LM20)
	int ret = sof_static_topology_init(&g_nrf54lm20_static_topology);
	if (ret < 0)
		return ret;

	sof_static_pipeline_trigger(1, true);
	sof_static_pipeline_trigger(2, true);
	return 0;
#else
	return -ENODEV;
#endif
}
```

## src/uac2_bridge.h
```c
/* SPDX-License-Identifier: BSD-3-Clause
 *
 * Copyright (c) 2026 Sound Open Firmware (SOF) Project
 */

#ifndef __APP_UAC2_BRIDGE_H__
#define __APP_UAC2_BRIDGE_H__

struct sof;
struct uac2_ops;

/**
 * \brief Initialize static audio pipelines for the active Nordic platform.
 * \param[in] sof SOF context pointer.
 * \return 0 on success, negative errno on failure.
 */
int sof_static_pipelines_init(struct sof *sof);

/**
 * \brief Return the Zephyr USB Audio Class 2.0 callback table.
 * \return Pointer to static uac2_ops structure.
 */
const struct uac2_ops *sof_get_uac2_ops(void);

#endif /* __APP_UAC2_BRIDGE_H__ */
```

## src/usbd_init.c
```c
/*
 * Copyright (c) 2023 Nordic Semiconductor ASA
 * Copyright (c) 2026 Sound Open Firmware (SOF) Project
 *
 * SPDX-License-Identifier: Apache-2.0
 */

#include <stdint.h>

#include <zephyr/device.h>
#include <zephyr/usb/usbd.h>
#include <zephyr/usb/bos.h>
#include <zephyr/logging/log.h>
#include <sample_usbd.h>

LOG_MODULE_REGISTER(usbd_sample_config, LOG_LEVEL_INF);

static const char *const blocklist[] = {
	"dfu_dfu",
	NULL,
};

USBD_DEVICE_DEFINE(sample_usbd,
		   DEVICE_DT_GET(DT_NODELABEL(zephyr_udc0)),
		   CONFIG_SAMPLE_USBD_VID, CONFIG_SAMPLE_USBD_PID);

USBD_DESC_LANG_DEFINE(sample_lang);
USBD_DESC_MANUFACTURER_DEFINE(sample_mfr, CONFIG_SAMPLE_USBD_MANUFACTURER);

#if defined(CONFIG_PLATFORM_TEENSY41) && defined(CONFIG_TEENSY41_BOARD_B)
USBD_DESC_PRODUCT_DEFINE(sample_product, "SOF Teensy 4.1 Audio B");
#elif defined(CONFIG_PLATFORM_TEENSY41) && defined(CONFIG_TEENSY41_BOARD_A)
USBD_DESC_PRODUCT_DEFINE(sample_product, "SOF Teensy 4.1 Audio A");
#else
USBD_DESC_PRODUCT_DEFINE(sample_product, CONFIG_SAMPLE_USBD_PRODUCT);
#endif

IF_ENABLED(CONFIG_HWINFO, (USBD_DESC_SERIAL_NUMBER_DEFINE(sample_sn)));

USBD_DESC_CONFIG_DEFINE(fs_cfg_desc, "FS Configuration");
USBD_DESC_CONFIG_DEFINE(hs_cfg_desc, "HS Configuration");

static const uint8_t attributes = (IS_ENABLED(CONFIG_SAMPLE_USBD_SELF_POWERED) ?
				   USB_SCD_SELF_POWERED : 0) |
				  (IS_ENABLED(CONFIG_SAMPLE_USBD_REMOTE_WAKEUP) ?
				   USB_SCD_REMOTE_WAKEUP : 0);

USBD_CONFIGURATION_DEFINE(sample_fs_config,
			  attributes,
			  CONFIG_SAMPLE_USBD_MAX_POWER, &fs_cfg_desc);

USBD_CONFIGURATION_DEFINE(sample_hs_config,
			  attributes,
			  CONFIG_SAMPLE_USBD_MAX_POWER, &hs_cfg_desc);

#if defined(CONFIG_BOARD_TEENSY41) || defined(CONFIG_BOARD_TEENSY40)
static int teensy_reboot_to_dev(const struct usbd_context *const ctx,
				const struct usb_setup_packet *const setup,
				const struct net_buf *const buf)
{
	ARG_UNUSED(ctx);
	ARG_UNUSED(setup);
	ARG_UNUSED(buf);

	/* Trigger PJRC MKL02 bootloader companion to enter HalfKay HID mode */
	__asm__ volatile("bkpt #251");
	return 0;
}

USBD_VREQUEST_DEFINE(teensy_reboot_vreq, 0xFB, NULL, teensy_reboot_to_dev);
#endif

static void sample_fix_code_triple(struct usbd_context *uds_ctx,
				   const enum usbd_speed speed)
{
	if (IS_ENABLED(CONFIG_USBD_CDC_ACM_CLASS) ||
	    IS_ENABLED(CONFIG_USBD_CDC_ECM_CLASS) ||
	    IS_ENABLED(CONFIG_USBD_CDC_NCM_CLASS) ||
	    IS_ENABLED(CONFIG_USBD_MIDI2_CLASS) ||
	    IS_ENABLED(CONFIG_USBD_AUDIO2_CLASS) ||
	    IS_ENABLED(CONFIG_USBD_VIDEO_CLASS)) {
		usbd_device_set_code_triple(uds_ctx, speed,
					    USB_BCC_MISCELLANEOUS, 0x02, 0x01);
	} else {
		usbd_device_set_code_triple(uds_ctx, speed, 0, 0, 0);
	}
}

struct usbd_context *sample_usbd_setup_device(usbd_msg_cb_t msg_cb)
{
	int err;

	err = usbd_add_descriptor(&sample_usbd, &sample_lang);
	if (err) {
		LOG_ERR("Failed to initialize language descriptor (%d)", err);
		return NULL;
	}

	err = usbd_add_descriptor(&sample_usbd, &sample_mfr);
	if (err) {
		LOG_ERR("Failed to initialize manufacturer descriptor (%d)", err);
		return NULL;
	}

	err = usbd_add_descriptor(&sample_usbd, &sample_product);
	if (err) {
		LOG_ERR("Failed to initialize product descriptor (%d)", err);
		return NULL;
	}

	IF_ENABLED(CONFIG_HWINFO, (
		err = usbd_add_descriptor(&sample_usbd, &sample_sn);
		if (err) {
			LOG_ERR("Failed to initialize SN descriptor (%d)", err);
			return NULL;
		}
	))

	if (USBD_SUPPORTS_HIGH_SPEED &&
	    usbd_caps_speed(&sample_usbd) == USBD_SPEED_HS) {
		err = usbd_add_configuration(&sample_usbd, USBD_SPEED_HS,
					     &sample_hs_config);
		if (err) {
			LOG_ERR("Failed to add High-Speed configuration");
			return NULL;
		}

		err = usbd_register_all_classes(&sample_usbd, USBD_SPEED_HS, 1,
						blocklist);
		if (err) {
			LOG_ERR("Failed to register classes");
			return NULL;
		}

		sample_fix_code_triple(&sample_usbd, USBD_SPEED_HS);
	}

	err = usbd_add_configuration(&sample_usbd, USBD_SPEED_FS,
				     &sample_fs_config);
	if (err) {
		LOG_ERR("Failed to add Full-Speed configuration");
		return NULL;
	}

	err = usbd_register_all_classes(&sample_usbd, USBD_SPEED_FS, 1, blocklist);
	if (err) {
		LOG_ERR("Failed to register classes");
		return NULL;
	}

	sample_fix_code_triple(&sample_usbd, USBD_SPEED_FS);
	usbd_self_powered(&sample_usbd, attributes & USB_SCD_SELF_POWERED);

	if (msg_cb != NULL) {
		err = usbd_msg_register_cb(&sample_usbd, msg_cb);
		if (err) {
			LOG_ERR("Failed to register message callback");
			return NULL;
		}
	}

#if defined(CONFIG_BOARD_TEENSY41) || defined(CONFIG_BOARD_TEENSY40)
	err = usbd_device_register_vreq(&sample_usbd, &teensy_reboot_vreq);
	if (err) {
		LOG_ERR("Failed to register HalfKay reboot request (%d)", err);
	}
#endif

	return &sample_usbd;
}

struct usbd_context *sample_usbd_init_device(usbd_msg_cb_t msg_cb)
{
	int err;

	if (sample_usbd_setup_device(msg_cb) == NULL) {
		return NULL;
	}

	err = usbd_init(&sample_usbd);
	if (err) {
		LOG_ERR("Failed to initialize device support");
		return NULL;
	}

	return &sample_usbd;
}
```
